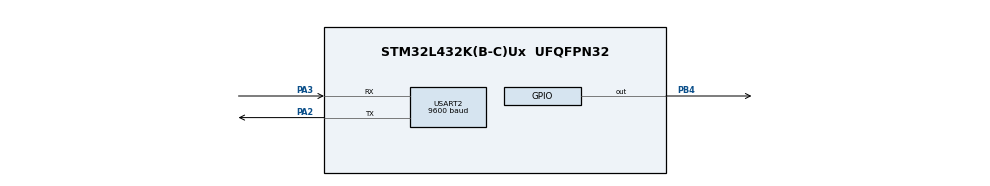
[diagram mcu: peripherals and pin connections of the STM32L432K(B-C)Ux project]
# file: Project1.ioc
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Mcu.Family=STM32L4
Mcu.Name=STM32L432K(B-C)Ux
Mcu.Package=UFQFPN32
NVIC.PriorityGroup=NVIC_PRIORITYGROUP_4
NVIC.USART2_IRQn=true\:0\:0\:false\:false\:true\:true\:true
PA13\ (JTMS-SWDIO).Mode=Serial_Wire
PA13\ (JTMS-SWDIO).Signal=SYS_JTMS-SWDIO
PA14\ (JTCK-SWCLK).Mode=Serial_Wire
PA14\ (JTCK-SWCLK).Signal=SYS_JTCK-SWCLK
PA2.Mode=Asynchronous
PA2.Signal=USART2_TX
PA3.Mode=Asynchronous
PA3.Signal=USART2_RX
PB4\ (NJTRST).Signal=GPIO_Output
ProjectManager.HeapSize=0x200
ProjectManager.StackSize=0x400
ProjectManager.TargetToolchain=MDK-ARM V5.27
RCC.HSE_VALUE=8000000
RCC.HSI48_VALUE=48000000
RCC.HSI_VALUE=16000000
RCC.LSE_VALUE=32768
RCC.MSI_VALUE=4000000
RCC.VCOOutputFreq_Value=32000000
USART2.BaudRate=9600
USART2.VirtualMode-Asynchronous=VM_ASYNC
board=custom

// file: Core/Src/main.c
/* USER CODE BEGIN Header */
/**
  ******************************************************************************
  * @file           : main.c
  * @brief          : Main program body
  ******************************************************************************
  * @attention
  *
  * <h2><center>&copy; Copyright (c) 2021 STMicroelectronics.
  * All rights reserved.</center></h2>
  *
  * This software component is licensed by ST under BSD 3-Clause license,
  * the "License"; You may not use this file except in compliance with the
  * License. You may obtain a copy of the License at:
  *                        opensource.org/licenses/BSD-3-Clause
  *
  ******************************************************************************
  */
/* USER CODE END Header */
#include "main.h"
#include "queue.h"

UART_HandleTypeDef huart2;

void SystemClock_Config(void);
static void MX_GPIO_Init(void);
static void MX_USART2_UART_Init(void);
static struct Queue* readyQueue;
static struct Queue* delayedQueue;
struct Task runningTask;

/* USER CODE BEGIN 0 */
volatile uint16_t timerFlag=0;

/* USER CODE END 0 */
void Init(){
    readyQueue = createQueue(1000);
    delayedQueue = createQueue(1000);
}

void QueTask(func task,int priority){
    if(priority >= 1 && priority <= 8 )
    {
        Enqueue(readyQueue, priority, 0, task);
    }
}

void Dispatch() {

		struct Task temp_task;
 int size = readyQueue->currentSize;
	 // If delayed queue is not empty, decrement the delay, if delay is 0 put in ready queue.
	 if(delayedQueue->currentSize > 0) {
		 int temp_size = delayedQueue->currentSize;
	  for(int i=0;i<temp_size;i++) {
			if(delayedQueue->tasksList[i].delay>0)
				delayedQueue->tasksList[i].delay--;

			if(delayedQueue->tasksList[i].delay==0) {
				temp_task = Dequeue(delayedQueue);
				Enqueue(readyQueue,temp_task.priority,temp_task.delay,temp_task.task);

			}
		}
	}
	 // ReadyQueue
		if(size>0)
		{
        runningTask = Dequeue(readyQueue);
        runningTask.task();
    }
		else
			HAL_UART_Transmit(&huart2,(uint8_t *)"Idle\r\n", sizeof("Idle\r\n"),500);

}
void ReRunMe(int delay) {
    runningTask.delay=delay;
    if(runningTask.delay==0)
        QueTask(runningTask.task, runningTask.priority);
    else
        Enqueue(delayedQueue,runningTask.priority,runningTask.delay,runningTask.task);
}
void TaskA(){
	   HAL_UART_Transmit(&huart2,(uint8_t *)"Task A\r\n", sizeof("Task A\r\n"),500);
	   HAL_GPIO_TogglePin(GPIOB,GPIO_PIN_3);
     //HAL_Delay(1000);
 //    ReRunMe(5);
}
void TaskB(){

	 //HAL_UART_Transmit(&huart2,(uint8_t *)HAL_GetTick, 1,500);
		 HAL_UART_Transmit(&huart2,(uint8_t *)"Task B\r\n", sizeof("Task B\r\n"),500);

	  //HAL_Delay(1000);
	// ReRunMe(10);
}
void TaskC(){

	 //HAL_UART_Transmit(&huart2,(uint8_t *)HAL_GetTick, 1,500);
		 HAL_UART_Transmit(&huart2,(uint8_t *)"Task C\r\n", sizeof("Task C\r\n"),500);

	  //HAL_Delay(1000);
	// ReRunMe(10);
}
void TaskD(){

	 //HAL_UART_Transmit(&huart2,(uint8_t *)HAL_GetTick, 1,500);
		 HAL_UART_Transmit(&huart2,(uint8_t *)"Task D\r\n", sizeof("Task D\r\n"),500);

	  //HAL_Delay(1000);
	// ReRunMe(10);
}
void TaskE(){

	 //HAL_UART_Transmit(&huart2,(uint8_t *)HAL_GetTick, 1,500);
		 HAL_UART_Transmit(&huart2,(uint8_t *)"Task E\r\n", sizeof("Task E\r\n"),500);

	  //HAL_Delay(1000);
	// ReRunMe(10);
}
int main(void)
{

  /* MCU Configuration--------------------------------------------------------*/

  /* Reset of all peripherals, Initializes the Flash interface and the Systick. */
  HAL_Init();

  /* Configure the system clock */
  SystemClock_Config();

  /* Initialize all configured peripherals */
  MX_GPIO_Init();
  MX_USART2_UART_Init();
	Init();
	QueTask(TaskA,5);
	QueTask(TaskB,4);
	QueTask(TaskC,3);
	QueTask(TaskD,2);
	QueTask(TaskE,1);

  /* Infinite loop */
  while (1)
  {
//		if(timerFlag == 1000){
//	HAL_Delay(500);
			Dispatch();
		//	timerFlag=0;
//		}

  }
}

void SystemClock_Config(void)
{
  RCC_OscInitTypeDef RCC_OscInitStruct = {0};
  RCC_ClkInitTypeDef RCC_ClkInitStruct = {0};
  RCC_PeriphCLKInitTypeDef PeriphClkInit = {0};

  /** Configure LSE Drive Capability
  */
  HAL_PWR_EnableBkUpAccess();
  __HAL_RCC_LSEDRIVE_CONFIG(RCC_LSEDRIVE_LOW);
  /** Initializes the RCC Oscillators according to the specified parameters
  * in the RCC_OscInitTypeDef structure.
  */
  RCC_OscInitStruct.OscillatorType = RCC_OSCILLATORTYPE_LSE|RCC_OSCILLATORTYPE_MSI;
  RCC_OscInitStruct.LSEState = RCC_LSE_ON;
  RCC_OscInitStruct.MSIState = RCC_MSI_ON;
  RCC_OscInitStruct.MSICalibrationValue = 0;
  RCC_OscInitStruct.MSIClockRange = RCC_MSIRANGE_6;
  RCC_OscInitStruct.PLL.PLLState = RCC_PLL_NONE;
  if (HAL_RCC_OscConfig(&RCC_OscInitStruct) != HAL_OK)
  {
    Error_Handler();
  }
  /** Initializes the CPU, AHB and APB buses clocks
  */
  RCC_ClkInitStruct.ClockType = RCC_CLOCKTYPE_HCLK|RCC_CLOCKTYPE_SYSCLK
                              |RCC_CLOCKTYPE_PCLK1|RCC_CLOCKTYPE_PCLK2;
  RCC_ClkInitStruct.SYSCLKSource = RCC_SYSCLKSOURCE_MSI;
  RCC_ClkInitStruct.AHBCLKDivider = RCC_SYSCLK_DIV1;
  RCC_ClkInitStruct.APB1CLKDivider = RCC_HCLK_DIV1;
  RCC_ClkInitStruct.APB2CLKDivider = RCC_HCLK_DIV1;

  if (HAL_RCC_ClockConfig(&RCC_ClkInitStruct, FLASH_LATENCY_0) != HAL_OK)
  {
    Error_Handler();
  }
  PeriphClkInit.PeriphClockSelection = RCC_PERIPHCLK_USART2;
  PeriphClkInit.Usart2ClockSelection = RCC_USART2CLKSOURCE_PCLK1;
  if (HAL_RCCEx_PeriphCLKConfig(&PeriphClkInit) != HAL_OK)
  {
    Error_Handler();
  }
  /** Configure the main internal regulator output voltage
  */
  if (HAL_PWREx_ControlVoltageScaling(PWR_REGULATOR_VOLTAGE_SCALE1) != HAL_OK)
  {
    Error_Handler();
  }
  /** Enable MSI Auto calibration
  */
  HAL_RCCEx_EnableMSIPLLMode();
}

static void MX_USART2_UART_Init(void)
{

  huart2.Instance = USART2;
  huart2.Init.BaudRate = 9600;
  huart2.Init.WordLength = UART_WORDLENGTH_8B;
  huart2.Init.StopBits = UART_STOPBITS_1;
  huart2.Init.Parity = UART_PARITY_NONE;
  huart2.Init.Mode = UART_MODE_TX_RX;
  huart2.Init.HwFlowCtl = UART_HWCONTROL_NONE;
  huart2.Init.OverSampling = UART_OVERSAMPLING_16;
  huart2.Init.OneBitSampling = UART_ONE_BIT_SAMPLE_DISABLE;
  huart2.AdvancedInit.AdvFeatureInit = UART_ADVFEATURE_NO_INIT;
  if (HAL_UART_Init(&huart2) != HAL_OK)
  {
    Error_Handler();
  }

}

static void MX_GPIO_Init(void)
{
  GPIO_InitTypeDef GPIO_InitStruct = {0};

  /* GPIO Ports Clock Enable */
  __HAL_RCC_GPIOC_CLK_ENABLE();
  __HAL_RCC_GPIOA_CLK_ENABLE();
  __HAL_RCC_GPIOB_CLK_ENABLE();

  /*Configure GPIO pin Output Level */
  HAL_GPIO_WritePin(GPIOB, GPIO_PIN_3, GPIO_PIN_RESET);

  /*Configure GPIO pin : PB3 */
  GPIO_InitStruct.Pin = GPIO_PIN_3;
  GPIO_InitStruct.Mode = GPIO_MODE_OUTPUT_PP;
  GPIO_InitStruct.Pull = GPIO_NOPULL;
  GPIO_InitStruct.Speed = GPIO_SPEED_FREQ_LOW;
  HAL_GPIO_Init(GPIOB, &GPIO_InitStruct);

}

void Error_Handler(void)
{
  __disable_irq();
  while (1)
  {
  }
}

/************************ (C) COPYRIGHT STMicroelectronics *****END OF FILE****/
